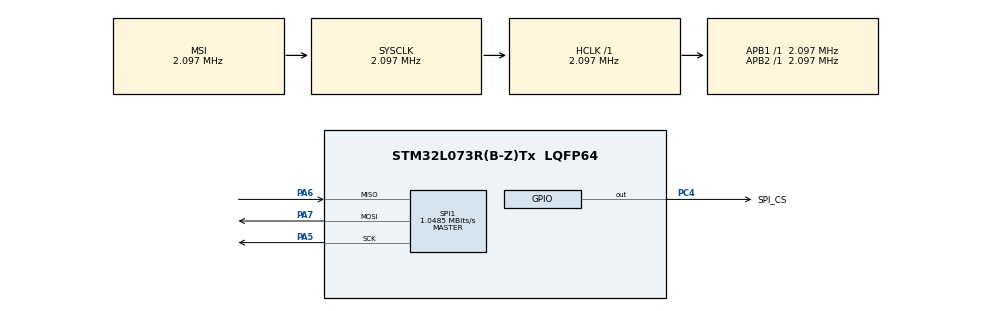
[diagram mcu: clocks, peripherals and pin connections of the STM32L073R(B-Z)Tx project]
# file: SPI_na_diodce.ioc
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Mcu.Family=STM32L0
Mcu.Name=STM32L073R(B-Z)Tx
Mcu.Package=LQFP64
NVIC.SPI1_IRQn=true\:0\:0\:false\:false\:true\:true\:true\:true
NVIC.TIM2_IRQn=true\:0\:0\:false\:false\:true\:true\:true\:true
PA5.Mode=Full_Duplex_Master
PA5.Signal=SPI1_SCK
PA6.Mode=Full_Duplex_Master
PA6.Signal=SPI1_MISO
PA7.Mode=Full_Duplex_Master
PA7.Signal=SPI1_MOSI
PC4.GPIO_Label=SPI_CS
PC4.PinState=GPIO_PIN_SET
PC4.Signal=GPIO_Output
ProjectManager.HeapSize=0x200
ProjectManager.StackSize=0x400
ProjectManager.TargetToolchain=STM32CubeIDE
RCC.AHBFreq_Value=2097000
RCC.APB1Freq_Value=2097000
RCC.APB1TimFreq_Value=2097000
RCC.APB2Freq_Value=2097000
RCC.APB2TimFreq_Value=2097000
RCC.HSE_VALUE=8000000
RCC.HSI16_VALUE=16000000
RCC.HSI48_VALUE=48000000
RCC.HSI_VALUE=16000000
RCC.LSE_VALUE=32768
RCC.MSI_VALUE=2097000
RCC.SYSCLKFreq_VALUE=2097000
RCC.VCOOutputFreq_Value=48000000
SPI1.CalculateBaudRate=1.0485 MBits/s
SPI1.Direction=SPI_DIRECTION_2LINES
SPI1.Mode=SPI_MODE_MASTER
SPI1.VirtualType=VM_MASTER
TIM2.Prescaler=2
VP_TIM2_VS_ClockSourceINT.Mode=Internal
board=custom

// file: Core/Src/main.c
/* USER CODE BEGIN Header */
/**
  ******************************************************************************
  * @file           : main.c
  * @brief          : Main program body
  ******************************************************************************
  * @attention
  *
  * Copyright (c) 2023 STMicroelectronics.
  * All rights reserved.
  *
  * This software is licensed under terms that can be found in the LICENSE file
  * in the root directory of this software component.
  * If no LICENSE file comes with this software, it is provided AS-IS.
  *
  ******************************************************************************
  */
/* USER CODE END Header */
#include "main.h"
#include "stm32l0xx_hal_spi.h"

SPI_HandleTypeDef hspi1;

TIM_HandleTypeDef htim2;

void SystemClock_Config(void);
static void MX_GPIO_Init(void);
static void MX_SPI1_Init(void);
static void MX_TIM2_Init(void);

int main(void)
{
  /* USER CODE BEGIN 1 */
	char uart_buf[50];
	  int uart_buf_len;
	  char spi_buf[20];
	  uint8_t addr;
	  uint8_t wip;

  /* USER CODE END 1 */

  /* MCU Configuration--------------------------------------------------------*/

  /* Reset of all peripherals, Initializes the Flash interface and the Systick. */
  HAL_Init();

  /* Configure the system clock */
  SystemClock_Config();

  /* Initialize all configured peripherals */
  MX_GPIO_Init();
  MX_SPI1_Init();
  MX_TIM2_Init();

  /* Infinite loop */
  while (1)
  {
	  HAL_GPIO_WritePin(CS_up_GPIO_Port, CS_up_Pin, GPIO_PIN_RESET);
	  HAL_SPI_Transmit(intf_ptr, &reg_addr, 1, 1000);
	  HAL_SPI_Receive(intf_ptr, reg_data, len, 1000);
	  HAL_GPIO_WritePin(CS_up_GPIO_Port, CS_up_Pin, GPIO_PIN_SET);
  }
}

void SystemClock_Config(void)
{
  RCC_OscInitTypeDef RCC_OscInitStruct = {0};
  RCC_ClkInitTypeDef RCC_ClkInitStruct = {0};

  /** Configure the main internal regulator output voltage
  */
  __HAL_PWR_VOLTAGESCALING_CONFIG(PWR_REGULATOR_VOLTAGE_SCALE1);

  /** Initializes the RCC Oscillators according to the specified parameters
  * in the RCC_OscInitTypeDef structure.
  */
  RCC_OscInitStruct.OscillatorType = RCC_OSCILLATORTYPE_MSI;
  RCC_OscInitStruct.MSIState = RCC_MSI_ON;
  RCC_OscInitStruct.MSICalibrationValue = 0;
  RCC_OscInitStruct.MSIClockRange = RCC_MSIRANGE_5;
  RCC_OscInitStruct.PLL.PLLState = RCC_PLL_NONE;
  if (HAL_RCC_OscConfig(&RCC_OscInitStruct) != HAL_OK)
  {
    Error_Handler();
  }

  /** Initializes the CPU, AHB and APB buses clocks
  */
  RCC_ClkInitStruct.ClockType = RCC_CLOCKTYPE_HCLK|RCC_CLOCKTYPE_SYSCLK
                              |RCC_CLOCKTYPE_PCLK1|RCC_CLOCKTYPE_PCLK2;
  RCC_ClkInitStruct.SYSCLKSource = RCC_SYSCLKSOURCE_MSI;
  RCC_ClkInitStruct.AHBCLKDivider = RCC_SYSCLK_DIV1;
  RCC_ClkInitStruct.APB1CLKDivider = RCC_HCLK_DIV1;
  RCC_ClkInitStruct.APB2CLKDivider = RCC_HCLK_DIV1;

  if (HAL_RCC_ClockConfig(&RCC_ClkInitStruct, FLASH_LATENCY_0) != HAL_OK)
  {
    Error_Handler();
  }
}

static void MX_SPI1_Init(void)
{

  /* SPI1 parameter configuration*/
  hspi1.Instance = SPI1;
  hspi1.Init.Mode = SPI_MODE_MASTER;
  hspi1.Init.Direction = SPI_DIRECTION_2LINES;
  hspi1.Init.DataSize = SPI_DATASIZE_8BIT;
  hspi1.Init.CLKPolarity = SPI_POLARITY_LOW;
  hspi1.Init.CLKPhase = SPI_PHASE_1EDGE;
  hspi1.Init.NSS = SPI_NSS_SOFT;
  hspi1.Init.BaudRatePrescaler = SPI_BAUDRATEPRESCALER_2;
  hspi1.Init.FirstBit = SPI_FIRSTBIT_MSB;
  hspi1.Init.TIMode = SPI_TIMODE_DISABLE;
  hspi1.Init.CRCCalculation = SPI_CRCCALCULATION_DISABLE;
  hspi1.Init.CRCPolynomial = 7;
  if (HAL_SPI_Init(&hspi1) != HAL_OK)
  {
    Error_Handler();
  }

}

static void MX_TIM2_Init(void)
{

  TIM_ClockConfigTypeDef sClockSourceConfig = {0};
  TIM_MasterConfigTypeDef sMasterConfig = {0};

  htim2.Instance = TIM2;
  htim2.Init.Prescaler = 2;
  htim2.Init.CounterMode = TIM_COUNTERMODE_UP;
  htim2.Init.Period = 65535;
  htim2.Init.ClockDivision = TIM_CLOCKDIVISION_DIV1;
  htim2.Init.AutoReloadPreload = TIM_AUTORELOAD_PRELOAD_DISABLE;
  if (HAL_TIM_Base_Init(&htim2) != HAL_OK)
  {
    Error_Handler();
  }
  sClockSourceConfig.ClockSource = TIM_CLOCKSOURCE_INTERNAL;
  if (HAL_TIM_ConfigClockSource(&htim2, &sClockSourceConfig) != HAL_OK)
  {
    Error_Handler();
  }
  sMasterConfig.MasterOutputTrigger = TIM_TRGO_RESET;
  sMasterConfig.MasterSlaveMode = TIM_MASTERSLAVEMODE_DISABLE;
  if (HAL_TIMEx_MasterConfigSynchronization(&htim2, &sMasterConfig) != HAL_OK)
  {
    Error_Handler();
  }

}

static void MX_GPIO_Init(void)
{
  GPIO_InitTypeDef GPIO_InitStruct = {0};

  /* GPIO Ports Clock Enable */
  __HAL_RCC_GPIOA_CLK_ENABLE();
  __HAL_RCC_GPIOC_CLK_ENABLE();

  /*Configure GPIO pin Output Level */
  HAL_GPIO_WritePin(SPI_CS_GPIO_Port, SPI_CS_Pin, GPIO_PIN_SET);

  /*Configure GPIO pin : SPI_CS_Pin */
  GPIO_InitStruct.Pin = SPI_CS_Pin;
  GPIO_InitStruct.Mode = GPIO_MODE_OUTPUT_PP;
  GPIO_InitStruct.Pull = GPIO_NOPULL;
  GPIO_InitStruct.Speed = GPIO_SPEED_FREQ_LOW;
  HAL_GPIO_Init(SPI_CS_GPIO_Port, &GPIO_InitStruct);

}

void Error_Handler(void)
{
  __disable_irq();
  while (1)
  {
  }
}
